# PIC16F1707 register map
Vendor: Microchip
Registers are 8-bit, read-write, reset 0x0 unless marked. A register's access mark holds for its fields unless they carry their own. Addresses are absolute, and some are shared; only a register's first bit layout is shown; [hi:lo] are bit positions; {n}, {i} and the like mark numbered series.

## SFR
0x00 INDF0 reset not defined — (power-on value xxxxxxxx)
0x01 INDF1 reset not defined — (power-on value xxxxxxxx)
0x02 PCL
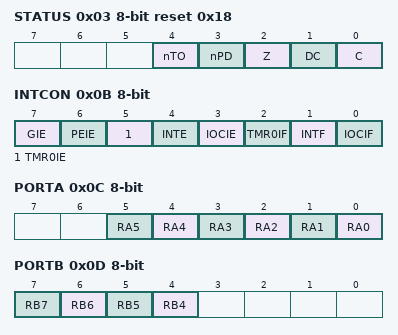
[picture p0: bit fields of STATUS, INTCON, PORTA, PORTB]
0x03 STATUS reset 0x18
  [4] nTO ro, [3] nPD ro, [2] Z, [1] DC, [0] C
0x04 FSR0L
0x05 FSR0H
0x06 FSR1L
0x07 FSR1H
0x08 BSR
  [4:0] BSR
0x09 WREG
  [7:0] WREG0
0x0A PCLATH
  [6:0] PCLATH
0x0B INTCON reset not defined — (power-on value 0000000x)
  [7] GIE, [6] PEIE, [5] TMR0IE, [4] INTE, [3] IOCIE, [2] TMR0IF, [1] INTF, [0] IOCIF ro
0x0C PORTA reset not defined — (power-on value --xxxxxx)
  [n] RA{n} (n=0..5)
0x0D PORTB reset not defined — (power-on value xxxx----)
  [n] RB{n} (n=4..7)
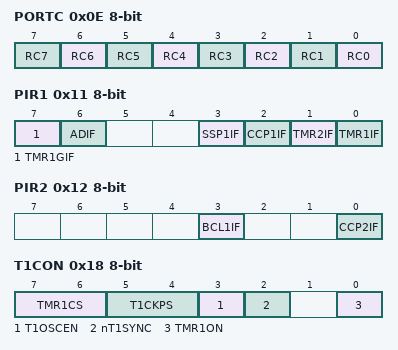
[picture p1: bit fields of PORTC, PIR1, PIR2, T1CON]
0x0E PORTC reset not defined — (power-on value xxxxxxxx)
  [n] RC{n} (n=0..7)
0x11 PIR1
  [7] TMR1GIF — Timer1 Gate Interrupt Flag bit
  [6] ADIF — A/D Converter Interrupt Flag bit
  [3] SSP1IF — Synchronous Serial Port (MSSP) Interrupt Flag bit
  [2] CCP1IF
  [1] TMR2IF — TMR2 to PR2 Match Interrupt Flag bit
  [0] TMR1IF — TMR1 Overflow Interrupt Flag bit
0x12 PIR2
  [3] BCL1IF — MSSP Bus Collision Interrupt Flag bit
  [0] CCP2IF
0x13 PIR3
  [4] ZCDIF
0x15 TMR0 reset not defined — (power-on value xxxxxxxx)
0x16 TMR1L reset not defined — (power-on value xxxxxxxx)
0x17 TMR1H reset not defined — (power-on value xxxxxxxx)
0x18 T1CON
  [7:6] TMR1CS, [5:4] T1CKPS, [3] T1OSCEN, [2] nT1SYNC, [0] TMR1ON
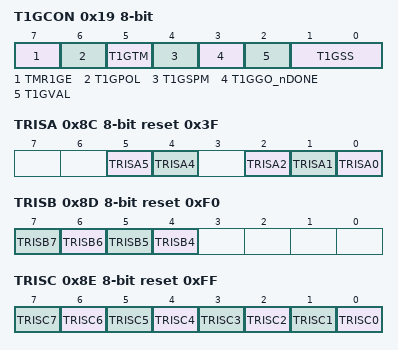
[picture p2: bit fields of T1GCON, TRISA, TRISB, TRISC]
0x19 T1GCON reset not defined — (power-on value 00000x00)
  [7] TMR1GE, [6] T1GPOL, [5] T1GTM, [4] T1GSPM, [3] T1GGO_nDONE, [2] T1GVAL ro, [1:0] T1GSS
0x8C TRISA reset 0x3F — PORTA Data Direction Control Register
  [5] TRISA5, [4] TRISA4, [2] TRISA2, [1] TRISA1, [0] TRISA0
0x8D TRISB reset 0xF0
  [n] TRISB{n} (n=4..7)
0x8E TRISC reset 0xFF — PORTC Data Direction Control Register
  [n] TRISC{n} (n=0..7)
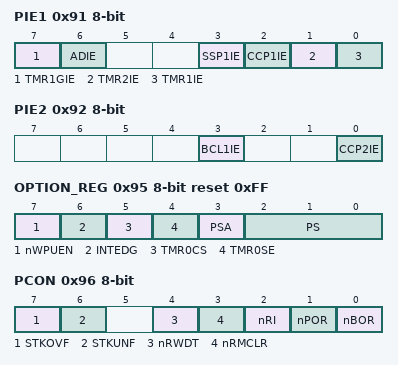
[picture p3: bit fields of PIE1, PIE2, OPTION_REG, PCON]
0x91 PIE1 — Peripheral Interrupt Enable Register 1
  [7] TMR1GIE — Timer1 Gate Interrupt Enable bit
  [6] ADIE — A/D Converter Interrupt Enable bit
  [3] SSP1IE
  [2] CCP1IE
  [1] TMR2IE — TMR2 to PR2 Match Interrupt Enable bit
  [0] TMR1IE — TMR1 Overflow Interrupt Enable bit
0x92 PIE2 — Peripheral Interrupt Enable Register 2
  [3] BCL1IE, [0] CCP2IE
0x93 PIE3 — Peripheral Interrupt Enable Register 3
  [4] ZCDIE
0x95 OPTION_REG reset 0xFF — Option Register
  [7] nWPUEN — Weak Pull-up Enable bit
  [6] INTEDG — Interrupt Edge Select bit
  [5] TMR0CS
  [4] TMR0SE — TMR0 Source Edge Select bit
  [3] PSA — Prescaler Active bit
  [2:0] PS
0x96 PCON reset not defined — Power Control Register (power-on value 00-111qq)
  [7] STKOVF — Stack Overflow Flag bit
  [6] STKUNF — Stack Underflow Flag bit
  [4] nRWDT
  [3] nRMCLR — MCLR Reset Flag bit
  [2] nRI — RESET Instruction Flag bit
  [1] nPOR — Power-on Reset Status bit
  [0] nBOR — Brown-out Reset Status bit
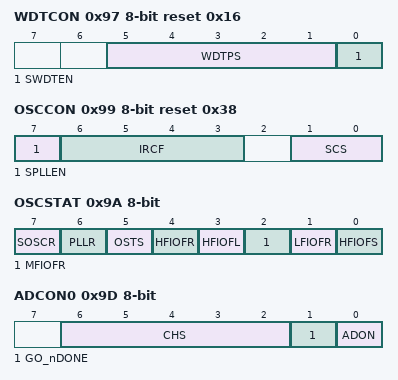
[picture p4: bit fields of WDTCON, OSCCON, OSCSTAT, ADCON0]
0x97 WDTCON reset 0x16 — Watchdog Timer Control Register
  [5:1] WDTPS
  [0] SWDTEN — Software Enable/Disable for Watch Dog Timer bit
0x98 OSCTUNE
  [5:0] TUN
0x99 OSCCON reset 0x38 — Oscillator Control Register
  [7] SPLLEN, [6:3] IRCF, [1:0] SCS
0x9A OSCSTAT ro reset not defined — Oscillator Status Register (power-on value 0qq00q0q)
  [7] SOSCR
  [6] PLLR
  [5] OSTS — Oscillator Start-up Time-out Status bit
  [4] HFIOFR
  [3] HFIOFL
  [2] MFIOFR
  [1] LFIOFR — Low Freqency Internal Oscillator Ready bit
  [0] HFIOFS — Low Freqency Internal Oscillator Ready bit
0x9B ADRESL reset not defined — A/D Result Register LSB (power-on value xxxxxxxx)
0x9C ADRESH reset not defined — A/D Result Register MSB (power-on value xxxxxxxx)
0x9D ADCON0 — Analog-to-Digital Control Register 0
  [6:2] CHS
  [1] GO_nDONE — A/D Conversion Status bit
  [0] ADON — A/D Module Enable bit
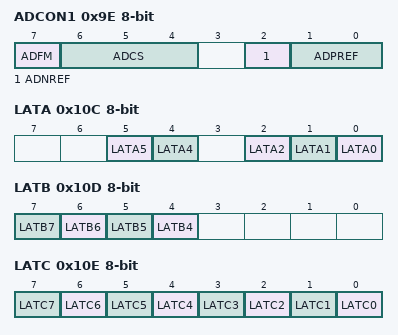
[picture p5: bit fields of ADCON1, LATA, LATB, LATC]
0x9E ADCON1 — Analog-to-Digital Control Register 1
  [7] ADFM — A/D Result Format Select bit
  [6:4] ADCS
  [2] ADNREF
  [1:0] ADPREF
0x9F ADCON2 — Analog-to-Digital Control Register 2
  [7:4] TRIGSEL
0x10C LATA reset not defined — (power-on value --xx-xxx)
  [5] LATA5, [4] LATA4, [2] LATA2, [1] LATA1, [0] LATA0
0x10D LATB reset not defined — (power-on value xxxx----)
  [n] LATB{n} (n=4..7)
0x10E LATC reset not defined — (power-on value xxxxxxxx)
  [n] LATC{n} (n=0..7)
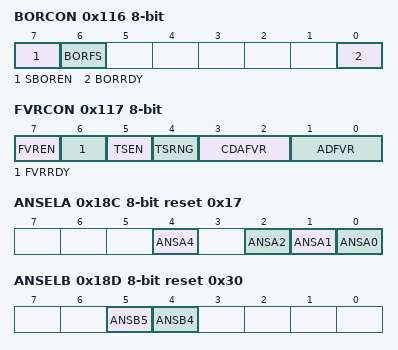
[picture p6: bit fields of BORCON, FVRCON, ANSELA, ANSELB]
0x116 BORCON reset not defined — Brown-out Reset Control Register (power-on value 10-----q)
  [7] SBOREN — Software Brown Out Reset Enable bit
  [6] BORFS
  [0] BORRDY ro — Brown-out Reset Circuit Ready Status bit
0x117 FVRCON reset not defined — Voltage Reference Control Register 0 (power-on value 0q000000)
  [7] FVREN — Fixed Voltage Reference Enable
  [6] FVRRDY ro — Fixed Voltage Reference Ready Flag
  [5] TSEN — Temperature Sensor Enable
  [4] TSRNG — Temperature Sensor Range Select
  [3:2] CDAFVR
  [1:0] ADFVR — A/D Converter Fixed Voltage Reference Selection
0x18C ANSELA reset 0x17
  [4] ANSA4, [2] ANSA2, [1] ANSA1, [0] ANSA0
0x18D ANSELB reset 0x30
  [5] ANSB5, [4] ANSB4
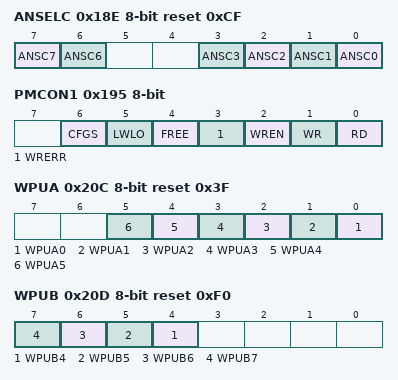
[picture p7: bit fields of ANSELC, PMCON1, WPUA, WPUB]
0x18E ANSELC reset 0xCF
  [7] ANSC7, [6] ANSC6, [n] ANSC{n} (n=0..3)
0x191 PMADRL
0x192 PMADRH reset 0x80
  [6:0] PMADRH
0x193 PMDATL reset not defined — (power-on value xxxxxxxx)
0x194 PMDATH reset not defined — (power-on value --xxxxxx)
  [5:0] PMDATH
0x195 PMCON1 reset not defined — (power-on value -000x000)
  [6] CFGS — FLASH Program / Data EEPROM or Configuration Select bit
  [5] LWLO — Load Write Latches Only bit
  [4] FREE — Program FLASH Erase Enable bit
  [3] WRERR — Sequence Error Flag bit
  [2] WREN — Program/Erase Enable bit
  [1] WR — Write Control bit (can only be set)
  [0] RD — Read Control bit (can only be set)
0x196 PMCON2 wo
0x197 VREGCON reset 0x1
  [1] VREGPM
0x20C WPUA reset 0x3F
  [n] WPUA{n} (n=0..5)
0x20D WPUB reset 0xF0
  [n] WPUB{n} (n=4..7)
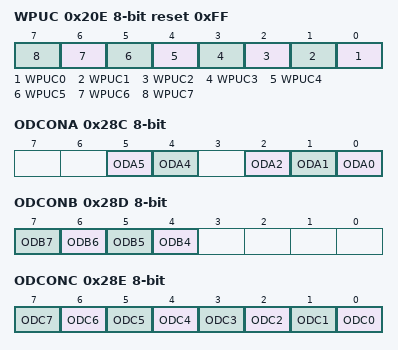
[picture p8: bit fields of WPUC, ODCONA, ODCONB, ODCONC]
0x20E WPUC reset 0xFF
  [n] WPUC{n} (n=0..7)
0x28C ODCONA
  [5] ODA5, [4] ODA4, [2] ODA2, [1] ODA1, [0] ODA0
0x28D ODCONB
  [n] ODB{n} (n=4..7)
0x28E ODCONC
  [n] ODC{n} (n=0..7)
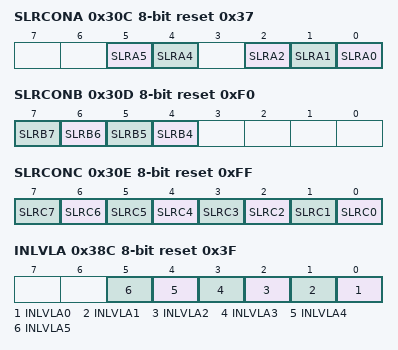
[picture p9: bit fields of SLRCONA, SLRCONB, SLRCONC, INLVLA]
0x30C SLRCONA reset 0x37
  [5] SLRA5, [4] SLRA4, [2] SLRA2, [1] SLRA1, [0] SLRA0
0x30D SLRCONB reset 0xF0
  [n] SLRB{n} (n=4..7)
0x30E SLRCONC reset 0xFF
  [n] SLRC{n} (n=0..7)
0x38C INLVLA reset 0x3F
  [n] INLVLA{n} (n=0..5)
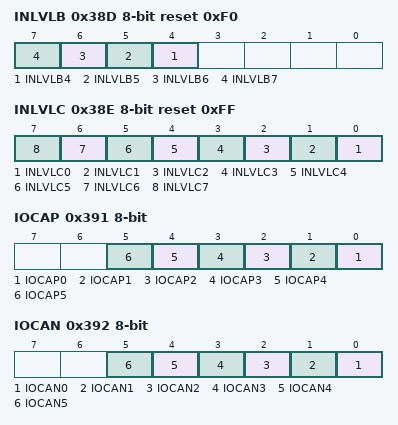
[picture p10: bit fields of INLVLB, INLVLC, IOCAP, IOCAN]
0x38D INLVLB reset 0xF0
  [n] INLVLB{n} (n=4..7)
0x38E INLVLC reset 0xFF
  [n] INLVLC{n} (n=0..7)
0x391 IOCAP
  [n] IOCAP{n} (n=0..5)
0x392 IOCAN
  [n] IOCAN{n} (n=0..5)
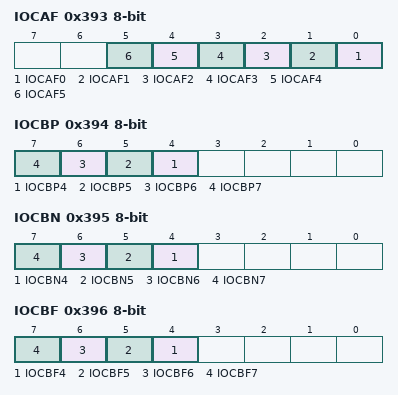
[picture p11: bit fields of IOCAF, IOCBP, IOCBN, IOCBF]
0x393 IOCAF
  [n] IOCAF{n} (n=0..5)
0x394 IOCBP
  [n] IOCBP{n} (n=4..7)
0x395 IOCBN
  [n] IOCBN{n} (n=4..7)
0x396 IOCBF
  [n] IOCBF{n} (n=4..7)
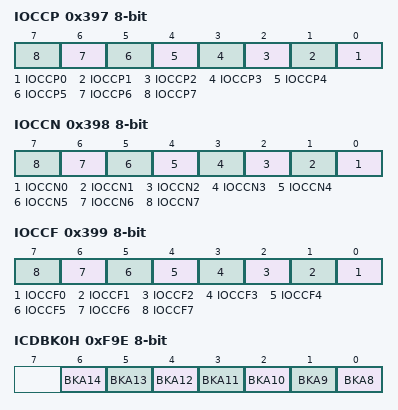
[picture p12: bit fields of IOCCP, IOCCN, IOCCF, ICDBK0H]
0x397 IOCCP
  [n] IOCCP{n} (n=0..7)
0x398 IOCCN
  [n] IOCCN{n} (n=0..7)
0x399 IOCCF
  [n] IOCCF{n} (n=0..7)
0xE0F PPSLOCK
  [0] PPSLOCKED
0xE10 INTPPS reset 0x2
  [4:0] INTPPS
0xE11 T0CKIPPS reset 0x2
  [4:0] T0CKIPPS
0xE12 T1CKIPPS reset 0x5
  [4:0] T1CKIPPS
0xE13 T1GPPS reset 0x4
  [4:0] T1GPPS
0xE14 CCP1PPS reset 0x15
  [4:0] CCP1PPS
0xE15 CCP2PPS reset 0x13
  [4:0] CCP2PPS
0xE20 SSPCLKPPS reset 0xE
  [4:0] SSPCLKPPS
0xE21 SSPDATPPS reset 0xC
  [4:0] SSPDATPPS
0xE22 SSPSSPPS reset 0x16
  [4:0] SSPSSPPS
{0xE90+i} RA{i}PPS (i=0..2)
  [4:0] RA{i}PPS
0xE94 RA4PPS
  [4:0] RA4PPS
0xE95 RA5PPS
  [4:0] RA5PPS
{0xE98+i} RB{i}PPS (i=4..7)
  [4:0] RB{i}PPS
{0xEA0+i} RC{i}PPS (i=0..7)
  [4:0] RC{i}PPS
0xF9E ICDBK0H reset not defined — (power-on value -xxxxxxx)
  [n-8] BKA{n} (n=8..14)
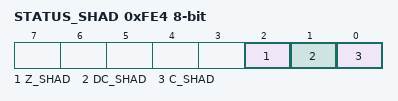
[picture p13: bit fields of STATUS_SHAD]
0xFE4 STATUS_SHAD reset not defined — (power-on value -----xxx)
  [2] Z_SHAD, [1] DC_SHAD, [0] C_SHAD
0xFE5 WREG_SHAD reset not defined — (power-on value xxxxxxxx)
0xFE6 BSR_SHAD reset not defined — (power-on value ---xxxxx)
  [4:0] BSR_SHAD
0xFE7 PCLATH_SHAD reset not defined — (power-on value -xxxxxxx)
  [6:0] PCLATH_SHAD
0xFE8 FSR0L_SHAD reset not defined — (power-on value xxxxxxxx)
0xFE9 FSR0H_SHAD reset not defined — (power-on value xxxxxxxx)
0xFEA FSR1L_SHAD reset not defined — (power-on value xxxxxxxx)
0xFEB FSR1H_SHAD reset not defined — (power-on value xxxxxxxx)
0xFED STKPTR reset not defined — (power-on value ---xxxxx)
  [4:0] STKPTR
0xFEE TOSL reset not defined — (power-on value xxxxxxxx)
0xFEF TOSH reset not defined — (power-on value -xxxxxxx)
  [6:0] TOSH
